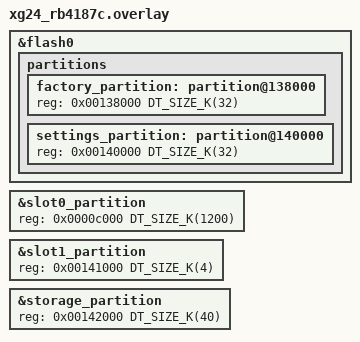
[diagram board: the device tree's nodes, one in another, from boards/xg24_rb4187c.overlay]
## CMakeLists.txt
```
# SPDX-License-Identifier: Apache-2.0

cmake_minimum_required(VERSION 3.28.0)

find_package(Zephyr REQUIRED HINTS $ENV{ZEPHYR_BASE})
project(openthread_shell)

target_sources(app PRIVATE src/main.c)
target_sources_ifdef(CONFIG_OT_SHELL_SAMPLE_RGB_STATUS_LED app PRIVATE src/rgb_status_led.c)
```

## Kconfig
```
# Copyright 2026 NXP
# SPDX-License-Identifier: Apache-2.0

mainmenu "OpenThread shell sample application"

config OT_SHELL_SAMPLE_RGB_STATUS_LED
	bool "Show the Thread device role on the RGB LED"
	depends on OPENTHREAD
	depends on $(dt_alias_enabled,red-pwm-led)
	depends on $(dt_alias_enabled,green-pwm-led)
	depends on $(dt_alias_enabled,blue-pwm-led)
	select PWM
	help
	  Blink the board RGB LED with a colour that reflects the current
	  OpenThread device role: disabled is white, detached is red, child
	  is yellow, router is green and leader is blue. When the shell is
	  enabled, an "rgb" command is added to control the LED.

if OT_SHELL_SAMPLE_RGB_STATUS_LED

config OT_SHELL_SAMPLE_RGB_STATUS_LED_BLINK_MS
	int "Default RGB LED blink period in milliseconds"
	default 500
	range 10 10000
	help
	  Initial time the LED stays on or off. It can be changed at run
	  time with the "rgb rate" shell command.

endif # OT_SHELL_SAMPLE_RGB_STATUS_LED

source "Kconfig.zephyr"
```

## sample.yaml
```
common:
  harness: net
  tags:
    - net
    - openthread
  depends_on: openthread
sample:
  description: Test Thread and IEEE 802.15.4 using the OpenThread shell
  name: OpenThread Shell
tests:
  sample.net.openthread.shell:
    build_only: true
    platform_allow:
      - nrf52840dk/nrf52840
      - nrf52840dongle/nrf52840
    integration_platforms:
      - nrf52840dk/nrf52840
  sample.net.openthread.shell.rw612_openthread_rcp_host:
    build_only: true
    extra_args:
      # Disabling monolithic since CI environment doesn't use blobs
      - CONFIG_NXP_MONOLITHIC_NBU=n
    platform_allow:
      - frdm_rw612
      - rd_rw612_bga
  sample.net.openthread.shell.mcxw_openthread_host:
    build_only: true
    extra_args:
      - EXTRA_CONF_FILE="prj-ot-host.conf"
    platform_allow:
      - frdm_mcxw71
      - frdm_mcxw72
      - mcxw72_evk
      - frdm_mcxw70
  sample.net.openthread.shell.esp:
    build_only: true
    extra_args:
      - CONFIG_BUILD_ONLY_NO_BLOBS=y
    platform_allow:
      - esp32c6_devkitc/esp32c6/hpcore
      - esp32h2_devkitm
  sample.net.openthread.shell.xg24:
    build_only: true
    extra_args:
      - CONFIG_BUILD_ONLY_NO_BLOBS=y
    platform_allow:
      - xg24_rb4186c
      - xg24_rb4187c
```

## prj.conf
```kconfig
# SPDX-License-Identifier: Apache-2.0

# Increased main stack size required for initialization
CONFIG_MAIN_STACK_SIZE=4096

# Enable Networking and OpenThread stack
CONFIG_NETWORKING=y
CONFIG_NET_L2_OPENTHREAD=y

# Use NVS as settings backend
CONFIG_NVS=y

# Logging
CONFIG_LOG=y
CONFIG_NET_LOG=y

# Networking and OpenThread shells
CONFIG_SHELL=y
CONFIG_NET_SHELL=y
CONFIG_OPENTHREAD_SHELL=y
```

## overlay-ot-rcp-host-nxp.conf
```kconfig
#
# Copyright 2025, NXP
#

# OS
CONFIG_MAIN_STACK_SIZE=8192

# CPP library
CONFIG_CPP=y

# IMU & FW loader
CONFIG_NXP_RF_IMU=y
CONFIG_NXP_FW_LOADER=y

# Shell
CONFIG_SHELL_ARGC_MAX=26
CONFIG_SHELL_CMD_BUFF_SIZE=512
CONFIG_SHELL_STACK_SIZE=5120

# Enable Openthread RCP host interface
CONFIG_HDLC_RCP_IF=y
CONFIG_OPENTHREAD_MANUAL_START=y

# Enable OpenThread features set
CONFIG_OPENTHREAD_THREAD_VERSION_1_3=y
CONFIG_OPENTHREAD_DHCP6_SERVER=y
CONFIG_OPENTHREAD_COMMISSIONER=y
CONFIG_OPENTHREAD_BORDER_AGENT=y
CONFIG_OPENTHREAD_BORDER_ROUTER=y
CONFIG_OPENTHREAD_UDP_FORWARD=y
CONFIG_OPENTHREAD_ENABLE_SERVICE=y
CONFIG_OPENTHREAD_EXTERNAL_HEAP=y
CONFIG_OPENTHREAD_PING_SENDER=y
CONFIG_OPENTHREAD_SLAAC=y
CONFIG_OPENTHREAD_SETTINGS_RAM=y
CONFIG_OPENTHREAD_NUM_MESSAGE_BUFFERS=256
CONFIG_OPENTHREAD_COAP=y
CONFIG_OPENTHREAD_JOINER=y
CONFIG_OPENTHREAD_REFERENCE_DEVICE=y
CONFIG_OPENTHREAD_DHCP6_CLIENT=y
CONFIG_OPENTHREAD_LINK_METRICS_INITIATOR=y
CONFIG_OPENTHREAD_LINK_METRICS_SUBJECT=y
CONFIG_OPENTHREAD_DUA=y
CONFIG_OPENTHREAD_MLR=y
CONFIG_OPENTHREAD_ECDSA=y
CONFIG_OPENTHREAD_DNS_CLIENT=y
CONFIG_OPENTHREAD_DNSSD_SERVER=y
CONFIG_OPENTHREAD_SRP_CLIENT=y
CONFIG_OPENTHREAD_SRP_SERVER=y
CONFIG_OPENTHREAD_MAC_FILTER=y
CONFIG_OPENTHREAD_IP6_FRAGM=y
```

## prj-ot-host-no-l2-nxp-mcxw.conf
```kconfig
# SPDX-License-Identifier: Apache-2.0

# Configuration file specific for NXP's MCXW platform

# Enable OpenThread as standalone module
CONFIG_NETWORKING=n
CONFIG_NET_L2_OPENTHREAD=n
CONFIG_OPENTHREAD=y
CONFIG_OPENTHREAD_SOURCES=y

# Module auto-init (replaces L2 init path)
CONFIG_OPENTHREAD_SYS_INIT=y

# Vendor specific radio implementation
CONFIG_OPENTHREAD_RADIO_VENDOR_IMPLEMENTATION=y
CONFIG_OPENTHREAD_RADIO_VENDOR_IMPLEMENTATION_FILE="nxp_mcxw_radio.c"
CONFIG_COUNTER=y
```

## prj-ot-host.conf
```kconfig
# SPDX-License-Identifier: Apache-2.0

# Enable Networking and OpenThread stack
CONFIG_NETWORKING=y
CONFIG_NET_L2_OPENTHREAD=y

# Networking and OpenThread shells
CONFIG_SHELL=y
CONFIG_NET_SHELL=y
CONFIG_OPENTHREAD_SHELL=y
CONFIG_NET_L2_IEEE802154_SHELL=y

# CPP library
CONFIG_CPP=y

# Shell
CONFIG_SHELL_ARGC_MAX=26
CONFIG_SHELL_CMD_BUFF_SIZE=512
CONFIG_SHELL_DEFAULT_TERMINAL_WIDTH=1024

# Flash
CONFIG_FLASH=y
CONFIG_FLASH_MAP=y

# Enable OpenThread features set
CONFIG_OPENTHREAD_MANUAL_START=y
CONFIG_OPENTHREAD_THREAD_VERSION_1_4=y
CONFIG_OPENTHREAD_PLATFORM_KEYS_EXPORTABLE_ENABLE=y
CONFIG_OPENTHREAD_DHCP6_SERVER=y
CONFIG_OPENTHREAD_COMMISSIONER=y
CONFIG_OPENTHREAD_BORDER_AGENT=y
CONFIG_OPENTHREAD_BORDER_ROUTER=y
CONFIG_OPENTHREAD_UDP_FORWARD=y
CONFIG_OPENTHREAD_ENABLE_SERVICE=y
CONFIG_OPENTHREAD_EXTERNAL_HEAP=y
CONFIG_OPENTHREAD_PING_SENDER=y
CONFIG_OPENTHREAD_SLAAC=y
CONFIG_OPENTHREAD_NUM_MESSAGE_BUFFERS=256
CONFIG_OPENTHREAD_COAP=y
CONFIG_OPENTHREAD_JOINER=y
CONFIG_OPENTHREAD_DHCP6_CLIENT=y
CONFIG_OPENTHREAD_LINK_METRICS_INITIATOR=y
CONFIG_OPENTHREAD_LINK_METRICS_SUBJECT=y
CONFIG_OPENTHREAD_DUA=y
CONFIG_OPENTHREAD_MLR=y
CONFIG_OPENTHREAD_ECDSA=y
CONFIG_OPENTHREAD_DNS_CLIENT=y
CONFIG_OPENTHREAD_DNSSD_SERVER=y
CONFIG_OPENTHREAD_SRP_CLIENT=y
CONFIG_OPENTHREAD_SRP_SERVER=y
CONFIG_OPENTHREAD_MAC_FILTER=y
CONFIG_OPENTHREAD_IP6_FRAGM=y
CONFIG_OPENTHREAD_TCP_ENABLE=y
CONFIG_OPENTHREAD_DNS_CLIENT_OVER_TCP=y
```

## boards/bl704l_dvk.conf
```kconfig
# SPDX-FileCopyrightText: Copyright The Zephyr Project Contributors
# SPDX-License-Identifier: Apache-2.0

# BL704L has only 80 KB RAM; trim the OpenThread shell sample to fit.

# Logging consumes several KB of RAM (buffers + dedicated thread stack).
CONFIG_LOG=n
CONFIG_NET_LOG=n

# Drop the networking shell; keep only the OpenThread shell for the test plan.
CONFIG_NET_SHELL=n

CONFIG_SHELL_STACK_SIZE=4096
CONFIG_HEAP_MEM_POOL_SIZE=2048

# OpenThread message buffers dominate RAM (128 B each); cut the pool.
CONFIG_OPENTHREAD_NUM_MESSAGE_BUFFERS=48

# The default DEVICE_ID_HASH secure-storage key provider relies on
# hwinfo_get_device_eui64()/uuid(), which BL704L doesn't provide, so the AEAD
# key can't be derived and the network key fails to persist (ot networkkey reads
# zero), blocking Thread attach. Use the entry-UID-hash provider instead.
CONFIG_SECURE_STORAGE_ITS_TRANSFORM_AEAD_KEY_PROVIDER_ENTRY_UID_HASH=y

# The mbedTLS AES round tables default to RAM (8 KB); keep them in flash.
CONFIG_MBEDTLS_AES_ROM_TABLES=y
```

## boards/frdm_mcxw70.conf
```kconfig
# Copyright 2026 NXP
# SPDX-License-Identifier: Apache-2.0

# OS
CONFIG_HEAP_MEM_POOL_SIZE=4096

#shell
CONFIG_SHELL_STACK_SIZE=4096

# Logging
CONFIG_LOG=n
CONFIG_NET_LOG=n

# Enabling the IEEE802154 CSL endpoint and OpenThread CSL receiver.
# The CSL receiver (OPENTHREAD_CONFIG_MAC_CSL_RECEIVER_ENABLE) is a Thread 1.2
# feature and fails to build against Thread 1.1 (sub_mac.hpp #error). Select
# Thread 1.2 explicitly so the version matches the CSL requirement; this also
# auto-enables OPENTHREAD_PLATFORM_USEC_TIMER (required for the CSL RX timing).
CONFIG_OPENTHREAD_THREAD_VERSION_1_2=y
CONFIG_IEEE802154_CSL_ENDPOINT=y
CONFIG_OPENTHREAD_CSL_RECEIVER=y


# Secure storage
CONFIG_SECURE_STORAGE_ITS_TRANSFORM_AEAD_KEY_PROVIDER_ENTRY_UID_HASH=y

# NVMEM write support: persist the IEEE 802.15.4 EUI-64 on boards
# that do not ship with a factory-programmed address.
CONFIG_NVMEM_FLASH_WRITE=y

# OpenThread worker thread stack (THREADIP-5758).
# During Thread commissioning the EC-JPAKE (P-256) DTLS handshake and the PSA
# SGI/PKC crypto path run on the OpenThread work-queue thread. With the default
# 6144 B this thread overflowed and triggered a USAGE FAULT (Zephyr fatal error
# 2, UFSR STKOF) that was caught by the MPU stack guard. Size it for the crypto
# path. Measured high-water mark was climbing past 6144 at the handshake.
CONFIG_OPENTHREAD_THREAD_STACK_SIZE=10240

# MPU hardware stack protection: trap any future stack overrun precisely at the
# thread boundary instead of silently corrupting adjacent RAM. Cheap to keep on.
CONFIG_HW_STACK_PROTECTION=y
CONFIG_MPU_STACK_GUARD=y

# HW crypto Flash trim (THREADIP-5758, Step 4).
# The SGI/PKC HW accelerator driver does not declare any MBEDTLS_PSA_ACCEL_*
# macros, so TF-PSA-Crypto still compiles the mbedTLS SW builtins alongside the
# HW path; the PSA_WANT_* algorithm symbols cannot simply be dropped because
# they are all genuinely used (GCM by the secure-storage ITS AEAD transform,
# CCM/CMAC/SHA-256/ECDSA/EC-JPAKE by OpenThread). The one HW CLIB component that
# Thread never exercises is RSA: Thread only uses ECC P-256 (ECDSA and
# EC-JPAKE), so the mcuxClRsa sources can be excluded from the build to reclaim
# Flash without affecting any validated crypto operation.
CONFIG_SGI_PKC_RSA=n
```

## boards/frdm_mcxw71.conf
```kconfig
# Copyright 2025 NXP
# SPDX-License-Identifier: Apache-2.0

# OS
CONFIG_HEAP_MEM_POOL_SIZE=2048
CONFIG_MAIN_STACK_SIZE=2048

#shell
CONFIG_SHELL_STACK_SIZE=2048

# Logging
CONFIG_LOG=n
CONFIG_NET_LOG=n

# Enabling the IEEE802154 CSL endpoint and OpenThread CSL receiver
CONFIG_IEEE802154_CSL_ENDPOINT=y
CONFIG_OPENTHREAD_CSL_RECEIVER=y

# Secure storage
CONFIG_SECURE_STORAGE_ITS_TRANSFORM_AEAD_KEY_PROVIDER_ENTRY_UID_HASH=y

# NVMEM write support: persist the IEEE 802.15.4 EUI-64 on boards
# that do not ship with a factory-programmed address.
CONFIG_NVMEM_FLASH_WRITE=y
```

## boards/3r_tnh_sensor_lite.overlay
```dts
/*
 * SPDX-FileCopyrightText: Copyright The Zephyr Project Contributors
 *
 * SPDX-License-Identifier: Apache-2.0
 */

/ {
	chosen {
		zephyr,ieee802154 = &ieee802154;
		zephyr,sram = &sram0;
	};
};

&ieee802154 {
	status = "okay";
};
```

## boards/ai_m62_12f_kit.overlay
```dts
/*
 * SPDX-FileCopyrightText: Copyright The Zephyr Project Contributors
 *
 * SPDX-License-Identifier: Apache-2.0
 */

/ {
	chosen {
		zephyr,ieee802154 = &ieee802154;
	};
};

&ieee802154 {
	status = "okay";
};
```

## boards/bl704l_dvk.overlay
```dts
/*
 * SPDX-FileCopyrightText: Copyright The Zephyr Project Contributors
 *
 * SPDX-License-Identifier: Apache-2.0
 */

/ {
	chosen {
		zephyr,ieee802154 = &ieee802154;
		/* Use the full SRAM; the BLE exchange-memory reservation
		 * (sram0_btle) is not needed for an 802.15.4-only build.
		 */
		zephyr,sram = &sram0;
	};
};

&ieee802154 {
	status = "okay";
};
```

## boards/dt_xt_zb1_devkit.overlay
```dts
/*
 * SPDX-FileCopyrightText: Copyright The Zephyr Project Contributors
 *
 * SPDX-License-Identifier: Apache-2.0
 */

/ {
	chosen {
		zephyr,ieee802154 = &ieee802154;
		/* Use the full SRAM; the BLE exchange-memory reservation
		 * (sram0_bt) is not needed for an 802.15.4-only build.
		 */
		zephyr,sram = &sram0;
	};
};

&ieee802154 {
	status = "okay";
};
```

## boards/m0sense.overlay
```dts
/*
 * SPDX-FileCopyrightText: Copyright The Zephyr Project Contributors
 *
 * SPDX-License-Identifier: Apache-2.0
 */

/ {
	chosen {
		zephyr,ieee802154 = &ieee802154;
		/* Use the full SRAM; the BLE exchange-memory reservation
		 * (sram0_bt) is not needed for an 802.15.4-only build.
		 */
		zephyr,sram = &sram0;
		/* Console/shell on UART0 (USB device stack dropped to fit the
		 * 384 KB code partition).
		 */
		zephyr,console = &uart0;
		zephyr,shell-uart = &uart0;
	};
};

&ieee802154 {
	status = "okay";
};
```

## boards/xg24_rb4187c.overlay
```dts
/*
 *    Copyright (c) 2025 Project CHIP Authors
 *    All rights reserved.
 *
 *    Licensed under the Apache License, Version 2.0 (the "License");
 *    you may not use this file except in compliance with the License.
 *    You may obtain a copy of the License at
 *
 *        http://www.apache.org/licenses/LICENSE-2.0
 *
 *    Unless required by applicable law or agreed to in writing, software
 *    distributed under the License is distributed on an "AS IS" BASIS
 *    WITHOUT WARRANTIES OR CONDITIONS OF ANY KIND, either express or implied.
 *    See the License for the specific language governing permissions and
 *    limitations under the License.
 */



&flash0 {
	partitions {
            factory_partition: partition@138000 {
                    reg = <0x00138000 DT_SIZE_K(32)>;
            };

            settings_partition: partition@140000 {
                    reg = <0x00140000 DT_SIZE_K(32)>;
            };
	};
};

&slot0_partition {
    reg = <0x0000c000 DT_SIZE_K(1200)>;
};

&slot1_partition {
    reg = <0x00141000 DT_SIZE_K(4)>;
};

/* Set 32 kB of storage at the end of the 1536 kB of flash */
&storage_partition {
    reg = <0x00142000 DT_SIZE_K(40)>;
};
```

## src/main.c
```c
/*
 * Copyright (c) 2024 A Labs GmbH
 *
 * SPDX-License-Identifier: Apache-2.0
 */

int main(void)
{
	/* Nothing to do here. The shell is automatically started in the background. */

	return 0;
}
```

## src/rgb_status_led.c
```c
/*
 * Copyright 2026 NXP
 *
 * SPDX-License-Identifier: Apache-2.0
 */

/*
 * Show the OpenThread device role on the board RGB LED:
 * disabled = white, detached = red, child = yellow,
 * router = green, leader = blue.
 */

#include <stdlib.h>

#include <zephyr/drivers/pwm.h>
#include <zephyr/init.h>
#include <zephyr/kernel.h>
#include <zephyr/shell/shell.h>

#include <openthread.h>
#include <openthread/instance.h>
#include <openthread/thread.h>

#define RGB_THREAD_STACK_SIZE 768
#define RGB_THREAD_PRIORITY   K_LOWEST_APPLICATION_THREAD_PRIO

struct rgb_color {
	uint8_t r;
	uint8_t g;
	uint8_t b;
};

static const struct pwm_dt_spec red_led = PWM_DT_SPEC_GET(DT_ALIAS(red_pwm_led));
static const struct pwm_dt_spec green_led = PWM_DT_SPEC_GET(DT_ALIAS(green_pwm_led));
static const struct pwm_dt_spec blue_led = PWM_DT_SPEC_GET(DT_ALIAS(blue_pwm_led));

static atomic_t blink_enabled = ATOMIC_INIT(1);
static atomic_t follow_role = ATOMIC_INIT(1);
static atomic_t blink_ms = ATOMIC_INIT(CONFIG_OT_SHELL_SAMPLE_RGB_STATUS_LED_BLINK_MS);
static atomic_t color; /* packed 0x00RRGGBB */

static void color_store(struct rgb_color c)
{
	atomic_set(&color, ((atomic_val_t)c.r << 16) | ((atomic_val_t)c.g << 8) | c.b);
}

static struct rgb_color color_load(void)
{
	atomic_val_t v = atomic_get(&color);

	return (struct rgb_color){
		.r = (v >> 16) & 0xff,
		.g = (v >> 8) & 0xff,
		.b = v & 0xff,
	};
}

static struct rgb_color role_to_color(otDeviceRole role)
{
	switch (role) {
	case OT_DEVICE_ROLE_DISABLED:
		return (struct rgb_color){255, 255, 255};
	case OT_DEVICE_ROLE_DETACHED:
		return (struct rgb_color){255, 0, 0};
	case OT_DEVICE_ROLE_CHILD:
		return (struct rgb_color){255, 255, 0};
	case OT_DEVICE_ROLE_ROUTER:
		return (struct rgb_color){0, 255, 0};
	case OT_DEVICE_ROLE_LEADER:
		return (struct rgb_color){0, 0, 255};
	default:
		return (struct rgb_color){0, 0, 0};
	}
}

static void led_set(const struct pwm_dt_spec *led, uint8_t level)
{
	uint32_t pulse = (uint32_t)(((uint64_t)led->period * level) / UINT8_MAX);

	(void)pwm_set_pulse_dt(led, pulse);
}

static void rgb_set(struct rgb_color c)
{
	led_set(&red_led, c.r);
	led_set(&green_led, c.g);
	led_set(&blue_led, c.b);
}

/* Must be called from outside the OpenThread context. */
static void color_from_current_role(void)
{
	otDeviceRole role;

	openthread_mutex_lock();
	role = otThreadGetDeviceRole(openthread_get_default_instance());
	openthread_mutex_unlock();

	color_store(role_to_color(role));
}

/* Runs in the OpenThread context with the OpenThread mutex held. */
static void ot_state_changed(otChangedFlags flags, void *user_data)
{
	ARG_UNUSED(user_data);

	if ((flags & OT_CHANGED_THREAD_ROLE) && atomic_get(&follow_role)) {
		color_store(role_to_color(
			otThreadGetDeviceRole(openthread_get_default_instance())));
	}
}

static struct openthread_state_changed_callback ot_state_cb = {
	.otCallback = ot_state_changed,
};

static void rgb_thread(void *p1, void *p2, void *p3)
{
	bool on = false;

	ARG_UNUSED(p1);
	ARG_UNUSED(p2);
	ARG_UNUSED(p3);

	color_from_current_role();

	while (true) {
		on = atomic_get(&blink_enabled) ? !on : false;
		rgb_set(on ? color_load() : (struct rgb_color){0, 0, 0});
		k_msleep((int32_t)atomic_get(&blink_ms));
	}
}

K_THREAD_STACK_DEFINE(rgb_stack, RGB_THREAD_STACK_SIZE);
static struct k_thread rgb_thread_data;

static int rgb_status_led_init(void)
{
	if (!pwm_is_ready_dt(&red_led) || !pwm_is_ready_dt(&green_led) ||
	    !pwm_is_ready_dt(&blue_led)) {
		return -ENODEV;
	}

	color_store(role_to_color(OT_DEVICE_ROLE_DISABLED));
	(void)openthread_state_changed_callback_register(&ot_state_cb);

	k_thread_create(&rgb_thread_data, rgb_stack, K_THREAD_STACK_SIZEOF(rgb_stack),
			rgb_thread, NULL, NULL, NULL, RGB_THREAD_PRIORITY, 0, K_NO_WAIT);
	k_thread_name_set(&rgb_thread_data, "rgb_status_led");

	return 0;
}

SYS_INIT(rgb_status_led_init, APPLICATION, CONFIG_APPLICATION_INIT_PRIORITY);

#if defined(CONFIG_SHELL)
static int parse_u8(const struct shell *sh, const char *arg, uint8_t *out)
{
	char *end;
	unsigned long v = strtoul(arg, &end, 10);

	if (*end != '\0' || v > UINT8_MAX) {
		shell_error(sh, "invalid value: %s (0-255)", arg);
		return -EINVAL;
	}

	*out = (uint8_t)v;
	return 0;
}

static int cmd_rgb_on(const struct shell *sh, size_t argc, char **argv)
{
	ARG_UNUSED(argc);
	ARG_UNUSED(argv);

	atomic_set(&blink_enabled, 1);
	shell_print(sh, "RGB LED on");
	return 0;
}

static int cmd_rgb_off(const struct shell *sh, size_t argc, char **argv)
{
	ARG_UNUSED(argc);
	ARG_UNUSED(argv);

	atomic_set(&blink_enabled, 0);
	shell_print(sh, "RGB LED off");
	return 0;
}

static int cmd_rgb_rate(const struct shell *sh, size_t argc, char **argv)
{
	char *end;
	unsigned long ms = strtoul(argv[1], &end, 10);

	ARG_UNUSED(argc);

	if (*end != '\0' || ms < 10 || ms > 10000) {
		shell_error(sh, "invalid period: %s (10-10000 ms)", argv[1]);
		return -EINVAL;
	}

	atomic_set(&blink_ms, (atomic_val_t)ms);
	shell_print(sh, "Blink period %lu ms", ms);
	return 0;
}

static int cmd_rgb_color(const struct shell *sh, size_t argc, char **argv)
{
	struct rgb_color c;

	ARG_UNUSED(argc);

	if (parse_u8(sh, argv[1], &c.r) || parse_u8(sh, argv[2], &c.g) ||
	    parse_u8(sh, argv[3], &c.b)) {
		return -EINVAL;
	}

	atomic_set(&follow_role, 0);
	color_store(c);
	shell_print(sh, "Colour %u %u %u (role tracking off)", c.r, c.g, c.b);
	return 0;
}

static int cmd_rgb_role(const struct shell *sh, size_t argc, char **argv)
{
	ARG_UNUSED(argc);
	ARG_UNUSED(argv);

	atomic_set(&follow_role, 1);
	color_from_current_role();
	shell_print(sh, "Colour follows the Thread device role");
	return 0;
}

SHELL_STATIC_SUBCMD_SET_CREATE(rgb_cmds,
	SHELL_CMD_ARG(on, NULL, "Enable blinking", cmd_rgb_on, 1, 0),
	SHELL_CMD_ARG(off, NULL, "Disable blinking", cmd_rgb_off, 1, 0),
	SHELL_CMD_ARG(rate, NULL, "Set blink period: rate <ms>", cmd_rgb_rate, 2, 0),
	SHELL_CMD_ARG(color, NULL, "Set a fixed colour: color <r> <g> <b>",
		      cmd_rgb_color, 4, 0),
	SHELL_CMD_ARG(role, NULL, "Follow the Thread device role", cmd_rgb_role, 1, 0),
	SHELL_SUBCMD_SET_END);

SHELL_CMD_REGISTER(rgb, &rgb_cmds, "RGB status LED control", NULL);
#endif /* CONFIG_SHELL */
```
